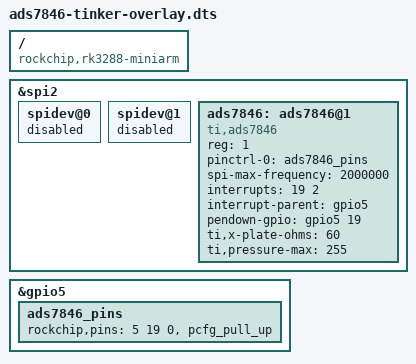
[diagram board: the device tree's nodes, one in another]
/*
 * Generic Device Tree overlay for the ADS7846 touch controller
 *
 */

/dts-v1/;
/plugin/;

/ {
	compatible = "rockchip,rk3288-miniarm", "rockchip,rk3288";

        fragment@0 {
                target = <&spi2>;

                __overlay__ {
                        status = "okay";

                        spidev@0 {
                                status = "disabled";
                        };

                        spidev@1 {
                                status = "disabled";
                        };
                };
        };

	fragment@1 {
		target = <&gpio5>;
		__overlay__ {
			ads7846_pins: ads7846_pins {
				rockchip,pins = <5 19 0 &pcfg_pull_up>;
			};
		};
	};

	fragment@2 {
		target = <&spi2>;
		__overlay__ {
			/* needed to avoid dtc warning */
			#address-cells = <1>;
			#size-cells = <0>;

			ads7846: ads7846@1 {
				compatible = "ti,ads7846";
				reg = <1>;			
				pinctrl-names = "default";
                                pinctrl-0 = <&ads7846_pins>;

				spi-max-frequency = <2000000>;
				interrupts = <19 2>; // high-to-low edge triggered
                                interrupt-parent = <&gpio5>;
				pendown-gpio = <&gpio5 19 0>;
				ti,x-plate-ohms = /bits/ 16 <60>;
				ti,pressure-max = /bits/ 16 <255>;
			};
		};
	};

/*
	__overrides__ {
		cs =     <&ads7846>,"reg:0";
		speed =  <&ads7846>,"spi-max-frequency:0";
		penirq = <&ads7846_pins>,"brcm,pins:0", // REQUIRED 
			 <&ads7846>,"interrupts:0",
			 <&ads7846>,"pendown-gpio:4";
		penirq_pull = <&ads7846_pins>,"brcm,pull:0";
		swapxy = <&ads7846>,"ti,swap-xy?";
		xmin =   <&ads7846>,"ti,x-min;0";
		ymin =   <&ads7846>,"ti,y-min;0";
		xmax =   <&ads7846>,"ti,x-max;0";
		ymax =   <&ads7846>,"ti,y-max;0";
		pmin =   <&ads7846>,"ti,pressure-min;0";
		pmax =   <&ads7846>,"ti,pressure-max;0";
		xohms =  <&ads7846>,"ti,x-plate-ohms;0";
	};
*/
};
